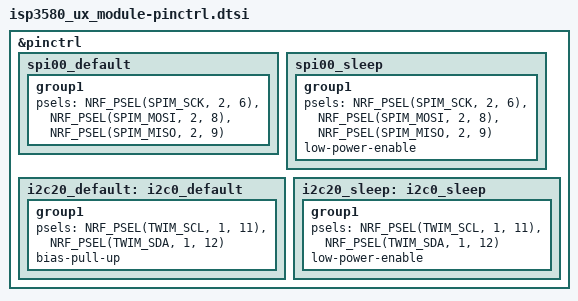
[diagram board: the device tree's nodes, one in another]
&pinctrl {
	/omit-if-no-ref/ spi00_default: spi00_default {
		group1 {
			psels = <NRF_PSEL(SPIM_SCK, 2, 6)>,
			        <NRF_PSEL(SPIM_MOSI, 2, 8)>,
			        <NRF_PSEL(SPIM_MISO, 2, 9)>;
		};
	};

	/omit-if-no-ref/ spi00_sleep: spi00_sleep {
		group1 {
			psels = <NRF_PSEL(SPIM_SCK, 2, 6)>,
			        <NRF_PSEL(SPIM_MOSI, 2, 8)>,
			        <NRF_PSEL(SPIM_MISO, 2, 9)>;
			low-power-enable;
		};
	};

	/omit-if-no-ref/ i2c20_default: i2c0_default {
		group1 {
			psels = <NRF_PSEL(TWIM_SCL, 1, 11)>,
					<NRF_PSEL(TWIM_SDA, 1, 12)>;
			bias-pull-up;
		};
	};

	/omit-if-no-ref/ i2c20_sleep: i2c0_sleep {
		group1 {
			psels = <NRF_PSEL(TWIM_SCL, 1, 11)>,
					<NRF_PSEL(TWIM_SDA, 1, 12)>;
			low-power-enable;
		};
	};
};
